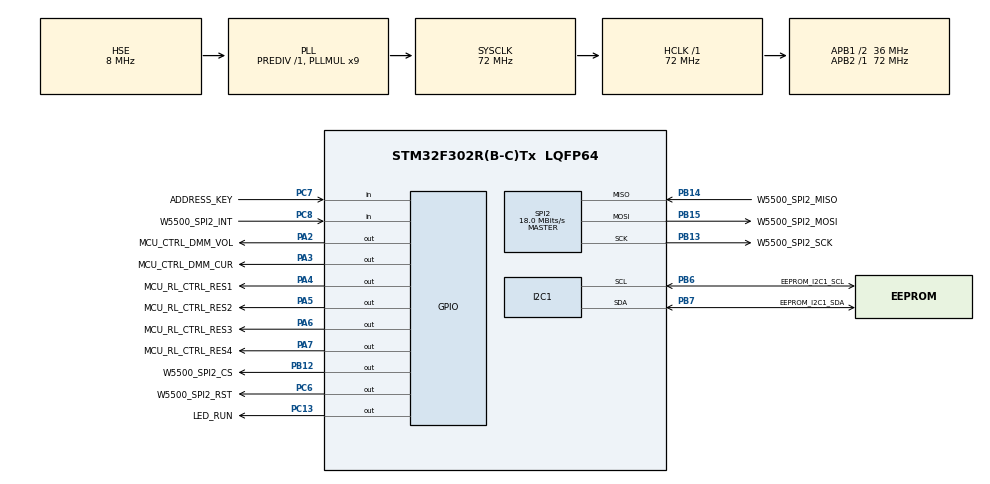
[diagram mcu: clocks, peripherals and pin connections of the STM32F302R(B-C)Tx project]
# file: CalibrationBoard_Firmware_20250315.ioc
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I2C1.Timing=0x00201D2B
Mcu.Family=STM32F3
Mcu.Name=STM32F302R(B-C)Tx
Mcu.Package=LQFP64
NVIC.PriorityGroup=NVIC_PRIORITYGROUP_4
PA13.Mode=Trace_Asynchronous_SW
PA13.Signal=SYS_JTMS-SWDIO
PA14.Mode=Trace_Asynchronous_SW
PA14.Signal=SYS_JTCK-SWCLK
PA2.GPIO_Label=MCU_CTRL_DMM_VOL
PA2.Signal=GPIO_Output
PA3.GPIO_Label=MCU_CTRL_DMM_CUR
PA3.Signal=GPIO_Output
PA4.GPIO_Label=MCU_RL_CTRL_RES1
PA4.Signal=GPIO_Output
PA5.GPIO_Label=MCU_RL_CTRL_RES2
PA5.Signal=GPIO_Output
PA6.GPIO_Label=MCU_RL_CTRL_RES3
PA6.Signal=GPIO_Output
PA7.GPIO_Label=MCU_RL_CTRL_RES4
PA7.Signal=GPIO_Output
PB12.GPIO_Label=W5500_SPI2_CS
PB12.Signal=GPIO_Output
PB13.GPIO_Label=W5500_SPI2_SCK
PB13.Mode=Full_Duplex_Master
PB13.Signal=SPI2_SCK
PB14.GPIO_Label=W5500_SPI2_MISO
PB14.Mode=Full_Duplex_Master
PB14.Signal=SPI2_MISO
PB15.GPIO_Label=W5500_SPI2_MOSI
PB15.Mode=Full_Duplex_Master
PB15.Signal=SPI2_MOSI
PB3.Mode=Trace_Asynchronous_SW
PB3.Signal=SYS_JTDO-TRACESWO
PB6.GPIO_Label=EEPROM_I2C1_SCL
PB6.Mode=I2C
PB6.Signal=I2C1_SCL
PB7.GPIO_Label=EEPROM_I2C1_SDA
PB7.Mode=I2C
PB7.Signal=I2C1_SDA
PC13.GPIO_Label=LED_RUN
PC13.Signal=GPIO_Output
PC6.GPIO_Label=W5500_SPI2_RST
PC6.Signal=GPIO_Output
PC7.GPIO_Label=ADDRESS_KEY
PC7.Signal=GPIO_Input
PC8.GPIO_Label=W5500_SPI2_INT
PC8.Signal=GPIO_Input
PF0-OSC_IN.Mode=HSE-External-Oscillator
PF0-OSC_IN.Signal=RCC_OSC_IN
PF1-OSC_OUT.Mode=HSE-External-Oscillator
PF1-OSC_OUT.Signal=RCC_OSC_OUT
ProjectManager.HeapSize=0x200
ProjectManager.StackSize=0x400
ProjectManager.TargetToolchain=MDK-ARM V5.32
RCC.AHBFreq_Value=72000000
RCC.APB1CLKDivider=RCC_HCLK_DIV2
RCC.APB1Freq_Value=36000000
RCC.APB1TimFreq_Value=72000000
RCC.APB2Freq_Value=72000000
RCC.APB2TimFreq_Value=72000000
RCC.CortexFreq_Value=72000000
RCC.HCLKFreq_Value=72000000
RCC.HSE_VALUE=8000000
RCC.HSI_VALUE=8000000
RCC.LSE_VALUE=32768
RCC.PLLMUL=RCC_PLL_MUL9
RCC.PLLSourceVirtual=RCC_PLLSOURCE_HSE
RCC.SYSCLKFreq_VALUE=72000000
RCC.SYSCLKSourceVirtual=RCC_SYSCLKSOURCE_PLLCLK
RCC.USBFreq_Value=72000000
SPI2.CalculateBaudRate=18.0 MBits/s
SPI2.DataSize=SPI_DATASIZE_8BIT
SPI2.Direction=SPI_DIRECTION_2LINES
SPI2.Mode=SPI_MODE_MASTER
SPI2.VirtualType=VM_MASTER
board=custom

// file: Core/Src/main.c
/* USER CODE BEGIN Header */
/**
  ******************************************************************************
  * @file           : main.c
  * @brief          : Main program body
  ******************************************************************************
  * @attention
  *
  * Copyright (c) 2025 STMicroelectronics.
  * All rights reserved.
  *
  * This software is licensed under terms that can be found in the LICENSE file
  * in the root directory of this software component.
  * If no LICENSE file comes with this software, it is provided AS-IS.
  *
  ******************************************************************************
  */
/* USER CODE END Header */
#include "main.h"
#include "i2c.h"
#include "spi.h"
#include "gpio.h"

/* USER CODE BEGIN Includes */
#include "app_modbus.h"
#include "app_net.h"
/* USER CODE END Includes */

void SystemClock_Config(void);

int main(void)
{

  /* MCU Configuration--------------------------------------------------------*/

  /* Reset of all peripherals, Initializes the Flash interface and the Systick. */
  HAL_Init();

  /* Configure the system clock */
  SystemClock_Config();

  /* Initialize all configured peripherals */
  MX_GPIO_Init();
  MX_I2C1_Init();
  MX_SPI2_Init();
  /* USER CODE BEGIN 2 */
  vApp_Modbus_DataInit();
  vApp_Net_Init(&aucModbusData[IP_START_REG][0]);
  /* USER CODE END 2 */

  /* Infinite loop */
  while (1)
  {

    /* USER CODE BEGIN 3 */
    vApp_DevPara_ResetCheck();

    vApp_ModbusTCP_Process();
  }
  /* USER CODE END 3 */
}

void SystemClock_Config(void)
{
  RCC_OscInitTypeDef RCC_OscInitStruct = {0};
  RCC_ClkInitTypeDef RCC_ClkInitStruct = {0};
  RCC_PeriphCLKInitTypeDef PeriphClkInit = {0};

  /** Initializes the RCC Oscillators according to the specified parameters
  * in the RCC_OscInitTypeDef structure.
  */
  RCC_OscInitStruct.OscillatorType = RCC_OSCILLATORTYPE_HSI|RCC_OSCILLATORTYPE_HSE;
  RCC_OscInitStruct.HSEState = RCC_HSE_ON;
  RCC_OscInitStruct.HSEPredivValue = RCC_HSE_PREDIV_DIV1;
  RCC_OscInitStruct.HSIState = RCC_HSI_ON;
  RCC_OscInitStruct.HSICalibrationValue = RCC_HSICALIBRATION_DEFAULT;
  RCC_OscInitStruct.PLL.PLLState = RCC_PLL_ON;
  RCC_OscInitStruct.PLL.PLLSource = RCC_PLLSOURCE_HSE;
  RCC_OscInitStruct.PLL.PLLMUL = RCC_PLL_MUL9;
  if (HAL_RCC_OscConfig(&RCC_OscInitStruct) != HAL_OK)
  {
    Error_Handler();
  }

  /** Initializes the CPU, AHB and APB buses clocks
  */
  RCC_ClkInitStruct.ClockType = RCC_CLOCKTYPE_HCLK|RCC_CLOCKTYPE_SYSCLK
                              |RCC_CLOCKTYPE_PCLK1|RCC_CLOCKTYPE_PCLK2;
  RCC_ClkInitStruct.SYSCLKSource = RCC_SYSCLKSOURCE_PLLCLK;
  RCC_ClkInitStruct.AHBCLKDivider = RCC_SYSCLK_DIV1;
  RCC_ClkInitStruct.APB1CLKDivider = RCC_HCLK_DIV2;
  RCC_ClkInitStruct.APB2CLKDivider = RCC_HCLK_DIV1;

  if (HAL_RCC_ClockConfig(&RCC_ClkInitStruct, FLASH_LATENCY_2) != HAL_OK)
  {
    Error_Handler();
  }
  PeriphClkInit.PeriphClockSelection = RCC_PERIPHCLK_I2C1;
  PeriphClkInit.I2c1ClockSelection = RCC_I2C1CLKSOURCE_HSI;
  if (HAL_RCCEx_PeriphCLKConfig(&PeriphClkInit) != HAL_OK)
  {
    Error_Handler();
  }
}

void Error_Handler(void)
{
  __disable_irq();
  while (1)
  {
  }
}
